# R7FA0E209 register map
Vendor: Renesas Electronics Corporation; Series: RA0; File version: 1.00.00
CPU: CM23 r1p0, little endian, no MPU, no FPU, VTOR, 2 interrupt priority bits, 64 interrupts
Registers are 16-bit, read-write, reset 0x0 unless marked. A register's access mark holds for its fields unless they carry their own. Offsets are from the block's base; [hi:lo] are bit positions; {n}, {i} and the like mark numbered series.

## PORT2 — Port 2 Control
Base 0x400A0040
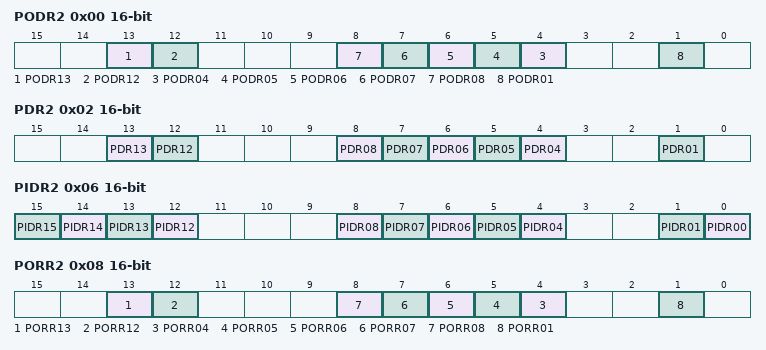
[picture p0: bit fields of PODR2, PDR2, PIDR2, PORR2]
0x00 PODR2 — Port 2 Output Data Register
  [all] fields
    0=Low output; 1=High output
  [13] PODR13 — P213 Output Data
  [12] PODR12 — P212 Output Data
  [n] PODR{n:02} (n=4..8) — P{n+200} Output Data
  [1] PODR01 — P201 Output Data
0x02 PDR2 — Port 2 Direction Register
  [all] fields
    0=Output 0; 1=Output 1
  [13] PDR13 — P213 Direction
  [12] PDR12 — P212 Direction
  [n] PDR{n:02} (n=4..8) — P{n+200} Direction
  [1] PDR01 — P201 Direction
0x06 PIDR2 ro (reset mask 0xE0C) — Port 2 State Register
  [all] fields
    0=Low level; 1=High level
  [n] PIDR{n} (n=12..15) — P{n+200} State
  [n] PIDR{n:02} (n=4..8) — P{n+200} State
  [1] PIDR01 — P201 State
  [0] PIDR00 — P200 State
0x08 PORR2 wo — Port 2 Output Reset Register
  [all] fields
    0=No effect on output; 1=Low output
  [13] PORR13 — P213 Output Reset
  [12] PORR12 — P212 Output Reset
  [n] PORR{n:02} (n=4..8) — P{n+200} Output Reset
  [1] PORR01 — P201 Output Reset
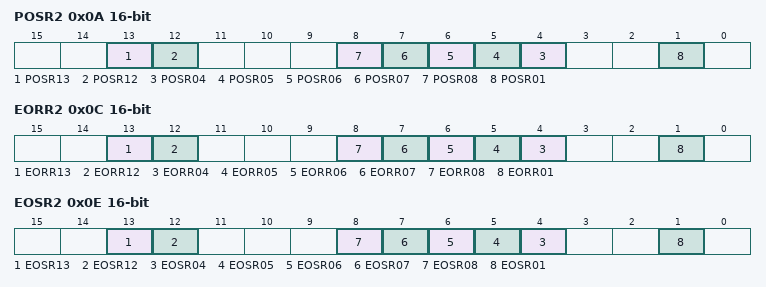
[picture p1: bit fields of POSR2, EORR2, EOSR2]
0x0A POSR2 wo — Port 2 Output Set Register
  [all] fields
    0=No effect on output; 1=High output
  [13] POSR13 — P213 Output Set
  [12] POSR12 — P212 Output Set
  [n] POSR{n:02} (n=4..8) — P{n+200} Output Set
  [1] POSR01 — P201 Output Set
0x0C EORR2 — Port 2 Event Output Reset Register
  [all] fields
    0=No effect on output; 1=Low output
  [13] EORR13 — P213 Event Output Reset
  [12] EORR12 — P212 Event Output Reset
  [n] EORR{n:02} (n=4..8) — P{n+200} Event Output Reset
  [1] EORR01 — P201 Event Output Reset
0x0E EOSR2 — Port 2 Event Output Set Register
  [all] fields
    0=No effect on output; 1=High output
  [13] EOSR13 — P213 Event Output Set
  [12] EOSR12 — P212 Event Output Set
  [n] EOSR{n:02} (n=4..8) — P{n+200} Event Output Set
  [1] EOSR01 — P201 Event Output Set

## PORT3 — Port 3 Control
Base 0x400A0060
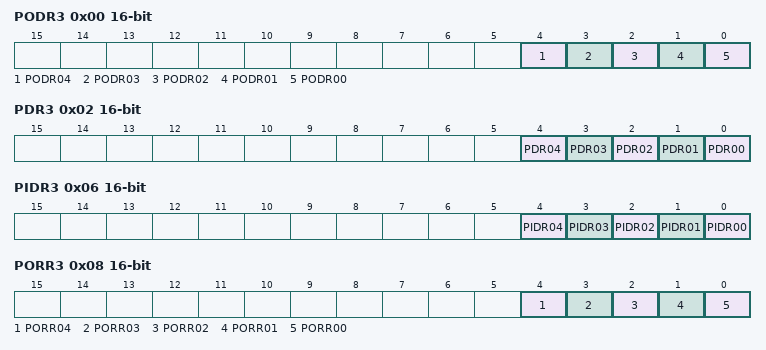
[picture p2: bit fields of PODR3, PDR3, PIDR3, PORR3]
0x00 PODR3 — Port 3 Output Data Register
  [all] fields
    0=Low output; 1=High output
  [4] PODR04 — P304 Output Data
  [3] PODR03 — P303 Output Data
  [2] PODR02 — P502 Output Data
  [1] PODR01 — P501 Output Data
  [0] PODR00 — P500 Output Data
0x02 PDR3 — Port 3 Direction Register
  [all] fields
    0=Output 0; 1=Output 1
  [4] PDR04 — P304 Direction
  [3] PDR03 — P303 Direction
  [2] PDR02 — P502 Direction
  [1] PDR01 — P501 Direction
  [0] PDR00 — P500 Direction
0x06 PIDR3 ro (reset mask 0xFFE0) — Port 3 State Register
  [all] fields
    0=Low level; 1=High level
  [4] PIDR04 — P304 State
  [3] PIDR03 — P303 State
  [2] PIDR02 — P502 State
  [1] PIDR01 — P501 State
  [0] PIDR00 — P500 State
0x08 PORR3 wo — Port 3 Output Reset Register
  [all] fields
    0=No effect on output; 1=Low output
  [4] PORR04 — P304 Output Reset
  [3] PORR03 — P303 Output Reset
  [2] PORR02 — P502 Output Reset
  [1] PORR01 — P501 Output Reset
  [0] PORR00 — P500 Output Reset
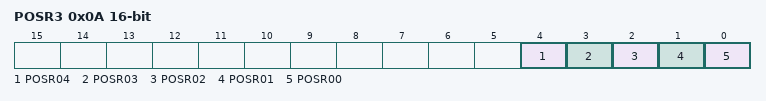
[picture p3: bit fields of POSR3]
0x0A POSR3 wo — Port 3 Output Set Register
  [all] fields
    0=No effect on output; 1=High output
  [4] POSR04 — P304 Output Set
  [3] POSR03 — P303 Output Set
  [2] POSR02 — P502 Output Set
  [1] POSR01 — P501 Output Set
  [0] POSR00 — P500 Output Set

## PORT4 — Port 4 Control
Base 0x400A0080
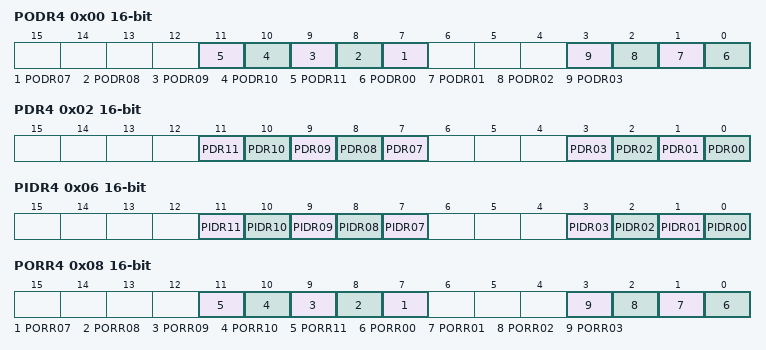
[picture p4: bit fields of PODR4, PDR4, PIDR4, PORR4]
0x00 PODR4 — Port 4 Output Data Register
  [all] fields
    0=Low output; 1=High output
  [n] PODR{n:02} (n=7..11) — P{n+400} Output Data
  [n] PODR{n:02} (n=0..3) — P{n+400} Output Data
0x02 PDR4 — Port 4 Direction Register
  [all] fields
    0=Output 0; 1=Output 1
  [n] PDR{n:02} (n=7..11) — P{n+400} Direction
  [n] PDR{n:02} (n=0..3) — P{n+400} Direction
0x06 PIDR4 ro (reset mask 0xF070) — Port 4 State Register
  [all] fields
    0=Low level; 1=High level
  [n] PIDR{n:02} (n=7..11) — P{n+400} State
  [n] PIDR{n:02} (n=0..3) — P{n+400} State
0x08 PORR4 wo — Port 4 Output Reset Register
  [all] fields
    0=No effect on output; 1=Low output
  [n] PORR{n:02} (n=7..11) — P{n+400} Output Reset
  [n] PORR{n:02} (n=0..3) — P{n+400} Output Reset
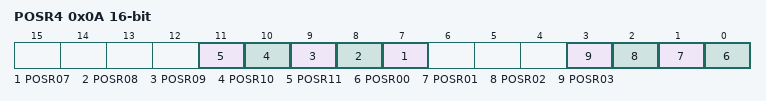
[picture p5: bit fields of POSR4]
0x0A POSR4 wo — Port 4 Output Set Register
  [all] fields
    0=No effect on output; 1=High output
  [n] POSR{n:02} (n=7..11) — P{n+400} Output Set
  [n] POSR{n:02} (n=0..3) — P{n+400} Output Set

## Notices in the file
This software is supplied by Renesas Electronics Corporation and is only intended for
use with Renesas products. No other uses are authorized. This software is owned by
Renesas Electronics Corporation and is protected under all applicable laws, including
copyright laws.
THIS SOFTWARE IS PROVIDED "AS IS" AND RENESAS MAKES NO WARRANTIES REGARDING
THIS SOFTWARE, WHETHER EXPRESS, IMPLIED OR STATUTORY, INCLUDING BUT NOT LIMITED TO
WARRANTIES OF MERCHANTABILITY, FITNESS FOR A PARTICULAR PURPOSE AND NON-INFRINGEMENT.
ALL SUCH WARRANTIES ARE EXPRESSLY DISCLAIMED. TO THE MAXIMUM EXTENT PERMITTED NOT
PROHIBITED BY LAW, NEITHER RENESAS ELECTRONICS CORPORATION NOR ANY OF ITS AFFILIATED
COMPANIES SHALL BE LIABLE FOR ANY DIRECT, INDIRECT, SPECIAL, INCIDENTAL OR CONSEQUENTIAL
DAMAGES FOR ANY REASON RELATED TO THIS SOFTWARE, EVEN IF RENESAS OR ITS AFFILIATES HAVE
BEEN ADVISED OF THE POSSIBILITY OF SUCH DAMAGES.
Renesas reserves the right, without notice, to make changes to this software and to
discontinue the availability of this software. By using this software, you agree to
the additional terms and conditions found by accessing the following link:
http://www.renesas.com/disclaimer
